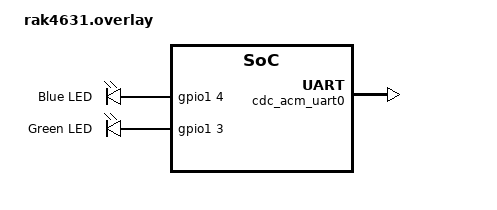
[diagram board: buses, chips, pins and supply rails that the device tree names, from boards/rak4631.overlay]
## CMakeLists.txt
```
# SPDX-License-Identifier: Apache-2.0

cmake_minimum_required(VERSION 3.20.0)

find_package(Zephyr REQUIRED HINTS $ENV{ZEPHYR_BASE})
project(mcuboot_rak)

target_sources(app PRIVATE src/main.c)

target_sources_ifdef(CONFIG_BT_PERIPHERAL app PRIVATE src/rak_ble_peripheral.c)
if(CONFIG_USE_SEGGER_RTT AND CONFIG_BOARD_RAK11720)
  target_sources(app PRIVATE src/rtt.c)
endif()
```

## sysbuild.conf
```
# Enable MCUboot bootloader support
SB_CONFIG_BOOTLOADER_MCUBOOT=y
# Do not forget to use your own key at your production code!!!
SB_CONFIG_BOOT_SIGNATURE_KEY_FILE="${APP_DIR}/../../key/rak_key_ecdsa-p256.pem"
SB_CONFIG_BOOT_SIGNATURE_TYPE_ECDSA_P256=y
```

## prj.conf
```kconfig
CONFIG_MAIN_STACK_SIZE=2048
CONFIG_SYSTEM_WORKQUEUE_STACK_SIZE=2048

CONFIG_LOG=y
CONFIG_LOG_PRINTK=n
# Open following lines to 
# use RTT logging for debug!!!
# CONFIG_USE_SEGGER_RTT=y
# CONFIG_LOG_BACKEND_RTT=y
# CONFIG_LOG_BACKEND_UART=n
```

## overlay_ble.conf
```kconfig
CONFIG_BT=y
CONFIG_BT_PERIPHERAL=y
CONFIG_BT_DEVICE_NAME="RAK"
CONFIG_BT_DEVICE_APPEARANCE=0
CONFIG_BT_GATT_CLIENT=y

# Bluetooth optimizations to allow larger data packets.
CONFIG_BT_RX_STACK_SIZE=2048
CONFIG_BT_L2CAP_TX_MTU=512
CONFIG_BT_BUF_ACL_RX_SIZE=502
CONFIG_BT_BUF_ACL_TX_SIZE=502
```

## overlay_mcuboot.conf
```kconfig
CONFIG_MCUMGR=y
CONFIG_NET_BUF=y
CONFIG_ZCBOR=y
CONFIG_CRC=y

# Enable flash operations.
CONFIG_FLASH=y
CONFIG_FLASH_MAP=y
CONFIG_IMG_MANAGER=y
CONFIG_STREAM_FLASH=y

# Enable most core commands.
CONFIG_MCUMGR_GRP_IMG=y
CONFIG_MCUMGR_GRP_OS=y

# Enable the storage erase command.
CONFIG_MCUMGR_GRP_ZBASIC=y
CONFIG_MCUMGR_GRP_ZBASIC_STORAGE_ERASE=y

# Enable the Shell mcumgr transport.
CONFIG_BASE64=y
CONFIG_CRC=y

# Enable the serial MCUmgr transport.
CONFIG_MCUMGR_TRANSPORT_UART=y

# Enable the BT MCUmgr transport.
# Close this line for RAK3172 board
CONFIG_MCUMGR_TRANSPORT_BT_REASSEMBLY=y

# Enable the mcumgr Packet Reassembly feature over Bluetooth and its configuration dependencies.
# MCUmgr buffer size is optimized to fit one SMP packet divided into five Bluetooth Write Commands,
# transmitted with the maximum possible MTU value: 498 bytes.
CONFIG_MCUMGR_TRANSPORT_NETBUF_SIZE=2475
CONFIG_MCUMGR_GRP_OS_MCUMGR_PARAMS=y
CONFIG_MCUMGR_TRANSPORT_WORKQUEUE_STACK_SIZE=4608

CONFIG_BOOTLOADER_MCUBOOT=y
```

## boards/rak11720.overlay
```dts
/ {
	aliases {
		blue-led = &blue_led;
		green-led = &green_led;
	};
};
```

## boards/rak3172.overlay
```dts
/ {
	chosen {
		zephyr,console = &lpuart1;
		zephyr,shell-uart = &lpuart1;
		zephyr,uart-mcumgr = &lpuart1;
	};

	aliases {
		blue-led = &blue_led;
		green-led = &green_led;
	};
};

&lpuart1 {
	pinctrl-0 = <&lpuart1_tx_pa2 &lpuart1_rx_pa3>;
	pinctrl-names = "default";
	current-speed = <115200>;
	status = "okay";
};
```

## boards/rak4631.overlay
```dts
/ {
	chosen {
		zephyr,console = &cdc_acm_uart0;
		zephyr,uart-mcumgr = &cdc_acm_uart0;
	};

	aliases {
		blue-led = &blue_led;
		green-led = &green_led;
	};

	leds {
		compatible = "gpio-leds";
		blue_led: led_2 {
			gpios = <&gpio1 4 GPIO_ACTIVE_HIGH>;
			label = "Blue LED";
		};
		green_led: led_1 {
			gpios = <&gpio1 3 GPIO_ACTIVE_HIGH>;
			label = "Green LED";
		};
	};
};

&reg1 {
	regulator-initial-mode = <NRF5X_REG_MODE_DCDC>;
};

&zephyr_udc0 {
	cdc_acm_uart0: cdc_acm_uart0 {
		compatible = "zephyr,cdc-acm-uart";
	};
};
```

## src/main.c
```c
#include <stdio.h>
#include <zephyr/kernel.h>
#include <zephyr/pm/device.h>
#include <zephyr/drivers/gpio.h>
#include <zephyr/drivers/lora.h>

#include "rak_ble_peripheral.h"

#include <zephyr/logging/log.h>
LOG_MODULE_REGISTER(main, LOG_LEVEL_DBG);

#if defined(CONFIG_BOARD_RAK4631)
static void configure_uicr(void) {
	if ((NRF_UICR->REGOUT0 & UICR_REGOUT0_VOUT_Msk) !=
		(UICR_REGOUT0_VOUT_3V3 << UICR_REGOUT0_VOUT_Pos)) {
		NRF_NVMC->CONFIG = NVMC_CONFIG_WEN_Wen;
		while (NRF_NVMC->READY == NVMC_READY_READY_Busy){}

		NRF_UICR->REGOUT0 = (NRF_UICR->REGOUT0 & ~((uint32_t)UICR_REGOUT0_VOUT_Msk)) |
							(UICR_REGOUT0_VOUT_3V3 << UICR_REGOUT0_VOUT_Pos);

		NRF_NVMC->CONFIG = NVMC_CONFIG_WEN_Ren;
		while (NRF_NVMC->READY == NVMC_READY_READY_Busy){}

		LOG_INF("REGOUT0 is updated!");

		// System reset is needed to update UICR registers.
		NVIC_SystemReset();
	}
}
#endif

int main(void)
{
#if defined(CONFIG_BOARD_RAK4631)
	configure_uicr();
#endif

#if defined(CONFIG_BT_PERIPHERAL)
	int ret = rak_ble_peripheral_init();
	if (ret) {
		LOG_ERR("Failed to init ble peripheral: %d", ret);
	}
#endif

	/* using __TIME__ ensure that a new binary will be built on every
	 * compile which is convenient when testing firmware upgrade.
	 */
	printk("build time: " __DATE__ " " __TIME__ "\n");

	while (1) {
		k_sleep(K_FOREVER);
	}

	return 0;
}
```

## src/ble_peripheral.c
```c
#include <stdio.h>

#include <zephyr/kernel.h>
#include <zephyr/device.h>

#include <zephyr/bluetooth/bluetooth.h>
#include <zephyr/bluetooth/hci.h>
#include <zephyr/bluetooth/conn.h>
#include <zephyr/bluetooth/gatt.h>

#include "ble_peripheral.h"

#include <zephyr/logging/log.h>
LOG_MODULE_REGISTER(ble_peripheral, LOG_LEVEL_INF);

#define DEVICE_NAME			CONFIG_BT_DEVICE_NAME
#define DEVICE_NAME_LEN		(sizeof(DEVICE_NAME) - 1)

#define BT_GAP_ADV_FAST_INT_MIN 1600  /* 1000 ms   */
#define BT_GAP_ADV_FAST_INT_MAX 1600  /* 1000 ms   */
/** Connectable advertising with @ref BT_LE_ADV_OPT_CONN */
#define BT_LE_ADV_CUSTOM BT_LE_ADV_PARAM(BT_LE_ADV_OPT_CONN, \
									BT_GAP_ADV_FAST_INT_MIN, \
									BT_GAP_ADV_FAST_INT_MAX, \
									NULL)

/* Advertising data */
static const struct bt_data ad[] = {
	BT_DATA_BYTES(BT_DATA_FLAGS, BT_LE_AD_NO_BREDR),
	BT_DATA_BYTES(BT_DATA_SVC_DATA16,
				0xaa, 0xfe, /* Eddystone UUID */
				0x10, /* Eddystone-URL frame type */
				0x00, /* Calibrated Tx power at 0m */
				0x01, /* URL Scheme Prefix https://www. */
				'r', 'a', 'k',
				'w', 'i', 'r', 'e', 'l', 'e', 's', 's',
				0x07 /* .com */
			)
};

/* Scan response data */
static const struct bt_data sd[] = {
	BT_DATA(BT_DATA_NAME_COMPLETE, DEVICE_NAME, DEVICE_NAME_LEN)
};

static void adv_start_work_handler(struct k_work *work) {
	bt_le_adv_stop();

	int err = bt_le_adv_start(BT_LE_ADV_CUSTOM, ad, ARRAY_SIZE(ad), sd, ARRAY_SIZE(sd));
	if (err) {
		LOG_ERR("Advertising failed to start (err %d)", err);
		return;
	}

	LOG_INF("Advertising successfully started");
}
K_WORK_DEFINE(adv_start_work, adv_start_work_handler);

static void mtu_updated(struct bt_conn *conn, uint16_t tx, uint16_t rx)
{
	printk("Updated MTU: TX: %d RX: %d bytes\n", tx, rx);
}

static struct bt_gatt_cb gatt_callbacks = {
	.att_mtu_updated = mtu_updated
};

static void connected(struct bt_conn *conn, uint8_t err)
{
	if (err) {
		printk("Connection failed, err 0x%02x %s\n", err, bt_hci_err_to_str(err));
	} else {
		printk("Connected\n");
	}
}

static void disconnected(struct bt_conn *conn, uint8_t reason)
{
	printk("Disconnected, reason 0x%02x %s\n", reason, bt_hci_err_to_str(reason));
	k_work_submit(&adv_start_work);
}

BT_CONN_CB_DEFINE(conn_callbacks) = {
	.connected = connected,
	.disconnected = disconnected,
};

static void bt_ready_handler(int err) {
	if (err) {
		LOG_ERR("Ble peripheral init failed (err %d)", err);
		return;
	}

	bt_gatt_cb_register(&gatt_callbacks);
	k_work_submit(&adv_start_work);
}

int ble_peripheral_init(void) {
	int err = bt_enable(bt_ready_handler);
	if (err) {
		LOG_ERR("Bluetooth init failed (err %d)", err);
		return err;
	}

	return err;
}
```

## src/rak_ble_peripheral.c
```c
#include <stdio.h>

#include <zephyr/kernel.h>
#include <zephyr/device.h>

#include <zephyr/bluetooth/bluetooth.h>
#include <zephyr/bluetooth/hci.h>
#include <zephyr/bluetooth/conn.h>
#include <zephyr/bluetooth/gatt.h>

#include "rak_ble_peripheral.h"

#include <zephyr/logging/log.h>
LOG_MODULE_REGISTER(ble_peripheral, LOG_LEVEL_INF);

#define DEVICE_NAME			CONFIG_BT_DEVICE_NAME
#define DEVICE_NAME_LEN		(sizeof(DEVICE_NAME) - 1)

#define BT_GAP_ADV_FAST_INT_MIN 1600  /* 1000 ms   */
#define BT_GAP_ADV_FAST_INT_MAX 1600  /* 1000 ms   */
/** Connectable advertising with @ref BT_LE_ADV_OPT_CONN */
#define BT_LE_ADV_CUSTOM BT_LE_ADV_PARAM(BT_LE_ADV_OPT_CONN, \
									BT_GAP_ADV_FAST_INT_MIN, \
									BT_GAP_ADV_FAST_INT_MAX, \
									NULL)

/* Advertising data */
static const struct bt_data ad[] = {
	BT_DATA_BYTES(BT_DATA_FLAGS, BT_LE_AD_NO_BREDR),
	BT_DATA_BYTES(BT_DATA_SVC_DATA16,
				0xaa, 0xfe, /* Eddystone UUID */
				0x10, /* Eddystone-URL frame type */
				0x00, /* Calibrated Tx power at 0m */
				0x01, /* URL Scheme Prefix https://www. */
				'r', 'a', 'k',
				'w', 'i', 'r', 'e', 'l', 'e', 's', 's',
				0x07 /* .com */
			)
};

/* Scan response data */
static const struct bt_data sd[] = {
	BT_DATA(BT_DATA_NAME_COMPLETE, DEVICE_NAME, DEVICE_NAME_LEN)
};

static void adv_start_work_handler(struct k_work *work) {
	bt_le_adv_stop();

	int err = bt_le_adv_start(BT_LE_ADV_CUSTOM, ad, ARRAY_SIZE(ad), sd, ARRAY_SIZE(sd));
	if (err) {
		LOG_ERR("Advertising failed to start (err %d)", err);
		return;
	}

	LOG_INF("Advertising successfully started");
}
K_WORK_DEFINE(adv_start_work, adv_start_work_handler);

static void mtu_updated(struct bt_conn *conn, uint16_t tx, uint16_t rx)
{
	printk("Updated MTU: TX: %d RX: %d bytes\n", tx, rx);
}

static struct bt_gatt_cb gatt_callbacks = {
	.att_mtu_updated = mtu_updated
};

static void connected(struct bt_conn *conn, uint8_t err)
{
	if (err) {
		printk("Connection failed, err 0x%02x %s\n", err, bt_hci_err_to_str(err));
	} else {
		printk("Connected\n");
	}
}

static void disconnected(struct bt_conn *conn, uint8_t reason)
{
	printk("Disconnected, reason 0x%02x %s\n", reason, bt_hci_err_to_str(reason));
	k_work_submit(&adv_start_work);
}

BT_CONN_CB_DEFINE(conn_callbacks) = {
	.connected = connected,
	.disconnected = disconnected,
};

static void bt_ready_handler(int err) {
	if (err) {
		LOG_ERR("Ble peripheral init failed (err %d)", err);
		return;
	}

	bt_gatt_cb_register(&gatt_callbacks);
	k_work_submit(&adv_start_work);
}

int rak_ble_peripheral_init(void) {
	int err = bt_enable(bt_ready_handler);
	if (err) {
		LOG_ERR("Bluetooth init failed (err %d)", err);
		return err;
	}

	return err;
}
```
